# MCU_CTRL_MMR_MCU_CTRL_MMR_CFG0_04500000h register map
Vendor: Texas Instruments
Registers are 32-bit, read-write, reset 0x0 unless marked. A register's access mark holds for its fields unless they carry their own. Offsets are as the file gives them; [hi:lo] are bit positions; lines under a group give offsets from that group; {n}, {i} and the like mark numbered series.

## MCU_CTRL_MMR_CFG0 (part 2 of 3)
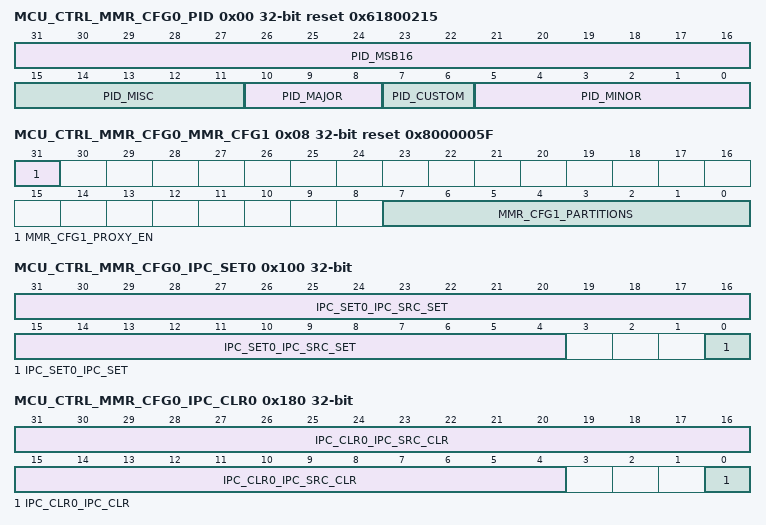
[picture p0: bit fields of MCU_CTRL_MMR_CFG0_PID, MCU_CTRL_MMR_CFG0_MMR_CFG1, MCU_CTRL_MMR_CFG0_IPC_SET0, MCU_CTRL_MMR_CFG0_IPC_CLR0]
0x00 MCU_CTRL_MMR_CFG0_PID ro reset 0x61800215
  [31:16] PID_MSB16 — Reset Source: mod_g_rst_n
  [15:11] PID_MISC — Reset Source: mod_g_rst_n
  [10:8] PID_MAJOR — Reset Source: mod_g_rst_n
  [7:6] PID_CUSTOM — Reset Source: mod_g_rst_n
  [5:0] PID_MINOR — Reset Source: mod_g_rst_n
0x08 MCU_CTRL_MMR_CFG0_MMR_CFG1 ro reset 0x8000005F
  [31] MMR_CFG1_PROXY_EN — Proxy addressing activated Reset Source: mod_por_rst_n
  [7:0] MMR_CFG1_PARTITIONS — Indicates present partitions Reset Source: mod_por_rst_n
0x100 MCU_CTRL_MMR_CFG0_IPC_SET0 access not given
  [31:4] IPC_SET0_IPC_SRC_SET — Read returns current valueWrite: 0 - No effect 1 - Sets both SRC_SETx and the SRC_CLRx bit in the corresponding IPC_CLR register Reset Source: mod_g_rst_n (access R/W1TS)
  [0] IPC_SET0_IPC_SET — Read returns 0Write: 0 - No effect 1 - Sets both the IPC_SET and the IPC_CLR bit in the corresponding IPC_CLR register Reset Source: mod_g_rst_n (access R/W1TS)
0x180 MCU_CTRL_MMR_CFG0_IPC_CLR0 access not given
  [31:4] IPC_CLR0_IPC_SRC_CLR — Read returns current valueWrite: 0 - No effect 1 - Clears both SRC_CLRx and the SRC_SETx bit in the corresponding IPC_GEN register Reset Source: mod_g_rst_n (access R/W1TC)
  [0] IPC_CLR0_IPC_CLR — Read returns current valueWrite: 0 - No effect 1 - Clears both IPC_CLR and the IPC_SET bit in the corresponding IPC_SET register Reset Source: mod_g_rst_n (access R/W1TC)
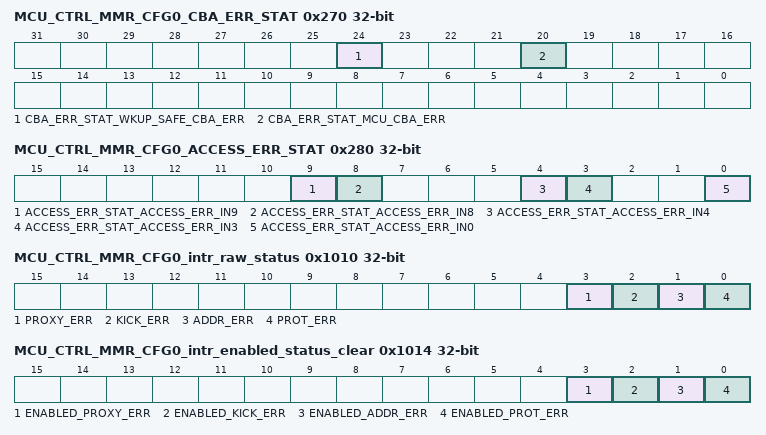
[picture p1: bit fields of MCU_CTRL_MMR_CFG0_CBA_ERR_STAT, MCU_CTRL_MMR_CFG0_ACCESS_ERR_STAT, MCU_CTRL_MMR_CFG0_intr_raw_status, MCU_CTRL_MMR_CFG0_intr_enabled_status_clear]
0x270 MCU_CTRL_MMR_CFG0_CBA_ERR_STAT ro
  [24] CBA_ERR_STAT_WKUP_SAFE_CBA_ERR — Access Error from Wkup Safe CBASS Reset Source: mod_g_rst_n
  [20] CBA_ERR_STAT_MCU_CBA_ERR — Access Error from MCU CBASS Reset Source: mod_g_rst_n
0x280 MCU_CTRL_MMR_CFG0_ACCESS_ERR_STAT ro
  [9] ACCESS_ERR_STAT_ACCESS_ERR_IN9 — Access Error Detected in MCU PadCfg MMR Reset Source: mod_por_rst_n
  [8] ACCESS_ERR_STAT_ACCESS_ERR_IN8 — Access Error Detected in MCU Ctrl MMR Reset Source: mod_por_rst_n
  [4] ACCESS_ERR_STAT_ACCESS_ERR_IN4 — Access Error Detected in MAIN PadCfg MMR Reset Source: mod_por_rst_n
  [3] ACCESS_ERR_STAT_ACCESS_ERR_IN3 — Access Error Detected in MAIN Ctrl MMR Reset Source: mod_por_rst_n
  [0] ACCESS_ERR_STAT_ACCESS_ERR_IN0 — Access Error Detected in WKUP Ctrl MMR Reset Source: mod_por_rst_n
{0x1008+0x4000*i} MCU_CTRL_MMR_CFG0_LOCK{i}_KICK0 (i=0..4)
  [31:0] LOCK{i}_KICK0 — - KICK0 component Reset Source: mod_g_rst_n
{0x100C+0x4000*i} MCU_CTRL_MMR_CFG0_LOCK{i}_KICK1 (i=0..4)
  [31:0] LOCK{i}_KICK1 — - KICK1 component Reset Source: mod_g_rst_n
0x1010 MCU_CTRL_MMR_CFG0_intr_raw_status access not given
  [3] PROXY_ERR — Proxy0 access violation error. Raw status is read. Write a 1 to set the status. Writing a 0 has no effect. Reset Source: mod_g_rst_n (access R/W1TS)
  [2] KICK_ERR — Kick access violation error. Raw status is read. Write a 1 to set the status. Writing a 0 has no effect. Reset Source: mod_g_rst_n (access R/W1TS)
  [1] ADDR_ERR — Addressing violation error. Raw status is read. Write a 1 to set the status. Writing a 0 has no effect. Reset Source: mod_g_rst_n (access R/W1TS)
  [0] PROT_ERR — Protection violation error. Raw status is read. Write a 1 to set the status. Writing a 0 has no effect. Reset Source: mod_g_rst_n (access R/W1TS)
0x1014 MCU_CTRL_MMR_CFG0_intr_enabled_status_clear access not given
  [3] ENABLED_PROXY_ERR — Proxy0 access violation error. Enabled status is read. Write a 1 to clear the status. Writing a 0 has no effect. Reset Source: mod_g_rst_n (access R/W1TC)
  [2] ENABLED_KICK_ERR — Kick access violation error. Enabled status is read. Write a 1 to clear the status. Writing a 0 has no effect. Reset Source: mod_g_rst_n (access R/W1TC)
  [1] ENABLED_ADDR_ERR — Addressing violation error. Enabled status is read. Write a 1 to clear the status. Writing a 0 has no effect. Reset Source: mod_g_rst_n (access R/W1TC)
  [0] ENABLED_PROT_ERR — Protection violation error. Enabled status is read. Write a 1 to clear the status. Writing a 0 has no effect. Reset Source: mod_g_rst_n (access R/W1TC)
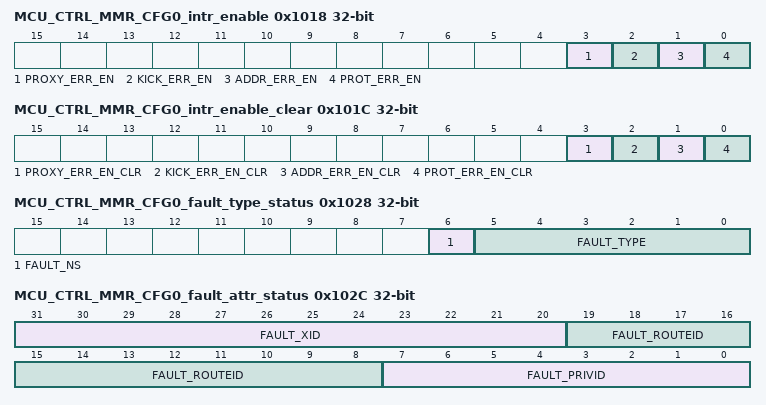
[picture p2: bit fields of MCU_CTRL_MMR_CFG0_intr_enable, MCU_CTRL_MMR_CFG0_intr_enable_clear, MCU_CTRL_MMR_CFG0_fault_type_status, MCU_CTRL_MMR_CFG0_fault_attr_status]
0x1018 MCU_CTRL_MMR_CFG0_intr_enable access not given
  [3] PROXY_ERR_EN — Proxy0 access violation error enable. Write a 1 to set the enable. Writing a 0 has no effect. Reset Source: mod_g_rst_n (access R/W1TS)
  [2] KICK_ERR_EN — Kick access violation error enable. Write a 1 to set the enable. Writing a 0 has no effect. Reset Source: mod_g_rst_n (access R/W1TS)
  [1] ADDR_ERR_EN — Addressing violation error enable. Write a 1 to set the enable. Writing a 0 has no effect. Reset Source: mod_g_rst_n (access R/W1TS)
  [0] PROT_ERR_EN — Protection violation error enable. Write a 1 to set the enable. Writing a 0 has no effect. Reset Source: mod_g_rst_n (access R/W1TS)
0x101C MCU_CTRL_MMR_CFG0_intr_enable_clear access not given
  [3] PROXY_ERR_EN_CLR — Proxy0 access violation error enable clear. Write a 1 to clear the enable. Writing a 0 has no effect. Reset Source: mod_g_rst_n (access R/W1TC)
  [2] KICK_ERR_EN_CLR — Kick access violation error enable clear. Write a 1 to clear the enable. Writing a 0 has no effect. Reset Source: mod_g_rst_n (access R/W1TC)
  [1] ADDR_ERR_EN_CLR — Addressing violation error enable clear. Write a 1 to clear the enable. Writing a 0 has no effect. Reset Source: mod_g_rst_n (access R/W1TC)
  [0] PROT_ERR_EN_CLR — Protection violation error enable clear. Write a 1 to clear the enable. Writing a 0 has no effect. Reset Source: mod_g_rst_n (access R/W1TC)
0x1020 MCU_CTRL_MMR_CFG0_eoi
  [7:0] EOI_VECTOR — EOI vector value. Write this with interrupt distribution value in the chip. Reset Source: mod_g_rst_n
0x1024 MCU_CTRL_MMR_CFG0_fault_address ro
  [31:0] FAULT_ADDR — Fault Address. Reset Source: mod_g_rst_n
0x1028 MCU_CTRL_MMR_CFG0_fault_type_status ro
  [6] FAULT_NS — Non-secure access. Reset Source: mod_g_rst_n
  [5:0] FAULT_TYPE — Fault Type 10_0000 = Supervisor read fault - priv = 1 dir = 1 dtype != 1 01_0000 = Supervisor write fault - priv = 1 dir = 0 00_1000 = Supervisor execute fault - priv = 1 dir = 1 dtype = 1 00_0100 = User read fault - priv = 0 dir = 1 dtype = 1 00_0010 = User write fault - priv = 0 dir = 0 00_0001 = User execute fault - priv = 0 dir = 1 dtype = 1 00_0000 = No fault Reset Source: mod_g_rst_n
0x102C MCU_CTRL_MMR_CFG0_fault_attr_status ro
  [31:20] FAULT_XID — XID. Reset Source: mod_g_rst_n
  [19:8] FAULT_ROUTEID — Route ID. Reset Source: mod_g_rst_n
  [7:0] FAULT_PRIVID — Privilege ID. Reset Source: mod_g_rst_n
0x1030 MCU_CTRL_MMR_CFG0_fault_clear wo
  [0] FAULT_CLR — Fault clear. Writing a 1 clears the current fault. Writing a 0 has no effect. Reset Source: mod_g_rst_n
{0x1100+4i} MCU_CTRL_MMR_CFG0_CLAIMREG_P0_R{i}_READONLY ro (i=0..5)
  [31:0] CLAIMREG_P0_R{i}_READONLY — Claim bits for Partition 0 Reset Source: mod_g_rst_n
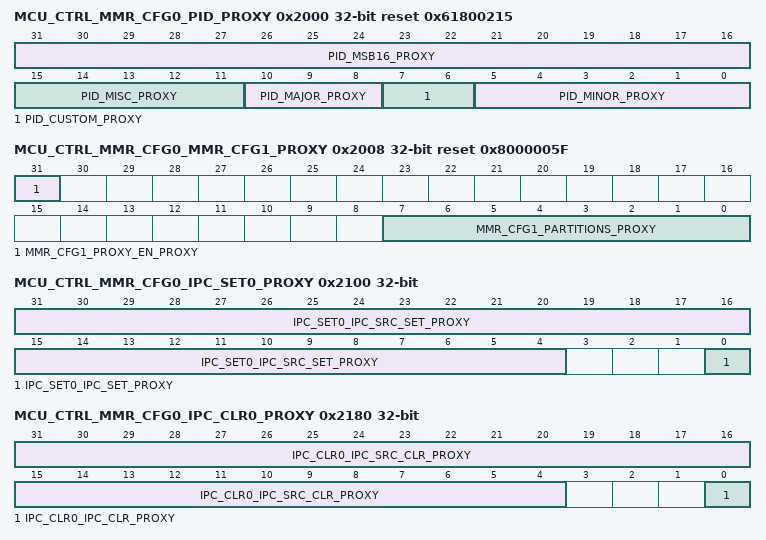
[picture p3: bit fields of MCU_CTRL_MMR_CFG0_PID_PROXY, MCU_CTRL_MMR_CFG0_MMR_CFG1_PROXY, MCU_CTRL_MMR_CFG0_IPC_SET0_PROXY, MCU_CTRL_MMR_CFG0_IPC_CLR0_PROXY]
0x2000 MCU_CTRL_MMR_CFG0_PID_PROXY ro reset 0x61800215
  [31:16] PID_MSB16_PROXY — Reset Source: mod_g_rst_n
  [15:11] PID_MISC_PROXY — Reset Source: mod_g_rst_n
  [10:8] PID_MAJOR_PROXY — Reset Source: mod_g_rst_n
  [7:6] PID_CUSTOM_PROXY — Reset Source: mod_g_rst_n
  [5:0] PID_MINOR_PROXY — Reset Source: mod_g_rst_n
0x2008 MCU_CTRL_MMR_CFG0_MMR_CFG1_PROXY ro reset 0x8000005F
  [31] MMR_CFG1_PROXY_EN_PROXY — Proxy addressing activated Reset Source: mod_por_rst_n
  [7:0] MMR_CFG1_PARTITIONS_PROXY — Indicates present partitions Reset Source: mod_por_rst_n
0x2100 MCU_CTRL_MMR_CFG0_IPC_SET0_PROXY access not given
  [31:4] IPC_SET0_IPC_SRC_SET_PROXY — Read returns current valueWrite: 0 - No effect 1 - Sets both SRC_SETx and the SRC_CLRx bit in the corresponding IPC_CLR register Reset Source: mod_g_rst_n (access R/W1TS)
  [0] IPC_SET0_IPC_SET_PROXY — Read returns 0Write: 0 - No effect 1 - Sets both the IPC_SET and the IPC_CLR bit in the corresponding IPC_CLR register Reset Source: mod_g_rst_n (access R/W1TS)
0x2180 MCU_CTRL_MMR_CFG0_IPC_CLR0_PROXY access not given
  [31:4] IPC_CLR0_IPC_SRC_CLR_PROXY — Read returns current valueWrite: 0 - No effect 1 - Clears both SRC_CLRx and the SRC_SETx bit in the corresponding IPC_GEN register Reset Source: mod_g_rst_n (access R/W1TC)
  [0] IPC_CLR0_IPC_CLR_PROXY — Read returns current valueWrite: 0 - No effect 1 - Clears both IPC_CLR and the IPC_SET bit in the corresponding IPC_SET register Reset Source: mod_g_rst_n (access R/W1TC)
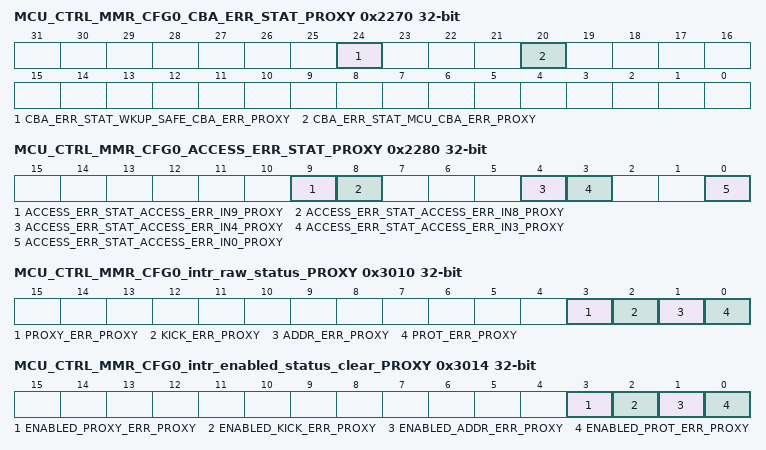
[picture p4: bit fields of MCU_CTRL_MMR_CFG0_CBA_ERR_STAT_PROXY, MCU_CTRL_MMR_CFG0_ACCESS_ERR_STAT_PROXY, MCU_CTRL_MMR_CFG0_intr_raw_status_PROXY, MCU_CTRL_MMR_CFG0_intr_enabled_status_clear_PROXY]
0x2270 MCU_CTRL_MMR_CFG0_CBA_ERR_STAT_PROXY ro
  [24] CBA_ERR_STAT_WKUP_SAFE_CBA_ERR_PROXY — Access Error from Wkup Safe CBASS Reset Source: mod_g_rst_n
  [20] CBA_ERR_STAT_MCU_CBA_ERR_PROXY — Access Error from MCU CBASS Reset Source: mod_g_rst_n
0x2280 MCU_CTRL_MMR_CFG0_ACCESS_ERR_STAT_PROXY ro
  [9] ACCESS_ERR_STAT_ACCESS_ERR_IN9_PROXY — Access Error Detected in MCU PadCfg MMR Reset Source: mod_por_rst_n
  [8] ACCESS_ERR_STAT_ACCESS_ERR_IN8_PROXY — Access Error Detected in MCU Ctrl MMR Reset Source: mod_por_rst_n
  [4] ACCESS_ERR_STAT_ACCESS_ERR_IN4_PROXY — Access Error Detected in MAIN PadCfg MMR Reset Source: mod_por_rst_n
  [3] ACCESS_ERR_STAT_ACCESS_ERR_IN3_PROXY — Access Error Detected in MAIN Ctrl MMR Reset Source: mod_por_rst_n
  [0] ACCESS_ERR_STAT_ACCESS_ERR_IN0_PROXY — Access Error Detected in WKUP Ctrl MMR Reset Source: mod_por_rst_n
{0x3008+0x4000*i} MCU_CTRL_MMR_CFG0_LOCK{i}_KICK0_PROXY (i=0..4)
  [31:0] LOCK{i}_KICK0_PROXY — - KICK0 component Reset Source: mod_g_rst_n
{0x300C+0x4000*i} MCU_CTRL_MMR_CFG0_LOCK{i}_KICK1_PROXY (i=0..4)
  [31:0] LOCK{i}_KICK1_PROXY — - KICK1 component Reset Source: mod_g_rst_n
0x3010 MCU_CTRL_MMR_CFG0_intr_raw_status_PROXY access not given
  [3] PROXY_ERR_PROXY — Proxy0 access violation error. Raw status is read. Write a 1 to set the status. Writing a 0 has no effect. Reset Source: mod_g_rst_n (access R/W1TS)
  [2] KICK_ERR_PROXY — Kick access violation error. Raw status is read. Write a 1 to set the status. Writing a 0 has no effect. Reset Source: mod_g_rst_n (access R/W1TS)
  [1] ADDR_ERR_PROXY — Addressing violation error. Raw status is read. Write a 1 to set the status. Writing a 0 has no effect. Reset Source: mod_g_rst_n (access R/W1TS)
  [0] PROT_ERR_PROXY — Protection violation error. Raw status is read. Write a 1 to set the status. Writing a 0 has no effect. Reset Source: mod_g_rst_n (access R/W1TS)
0x3014 MCU_CTRL_MMR_CFG0_intr_enabled_status_clear_PROXY access not given
  [3] ENABLED_PROXY_ERR_PROXY — Proxy0 access violation error. Enabled status is read. Write a 1 to clear the status. Writing a 0 has no effect. Reset Source: mod_g_rst_n (access R/W1TC)
  [2] ENABLED_KICK_ERR_PROXY — Kick access violation error. Enabled status is read. Write a 1 to clear the status. Writing a 0 has no effect. Reset Source: mod_g_rst_n (access R/W1TC)
  [1] ENABLED_ADDR_ERR_PROXY — Addressing violation error. Enabled status is read. Write a 1 to clear the status. Writing a 0 has no effect. Reset Source: mod_g_rst_n (access R/W1TC)
  [0] ENABLED_PROT_ERR_PROXY — Protection violation error. Enabled status is read. Write a 1 to clear the status. Writing a 0 has no effect. Reset Source: mod_g_rst_n (access R/W1TC)
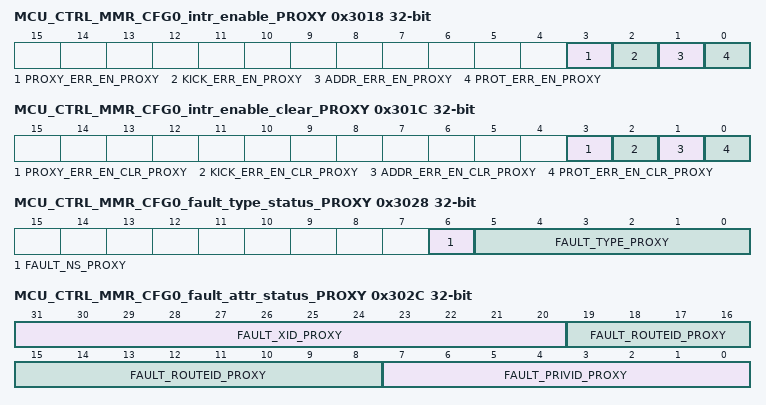
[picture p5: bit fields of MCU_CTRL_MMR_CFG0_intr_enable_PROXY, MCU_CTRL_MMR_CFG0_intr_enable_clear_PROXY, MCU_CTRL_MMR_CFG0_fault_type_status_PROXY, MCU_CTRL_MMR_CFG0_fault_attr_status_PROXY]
0x3018 MCU_CTRL_MMR_CFG0_intr_enable_PROXY access not given
  [3] PROXY_ERR_EN_PROXY — Proxy0 access violation error enable. Write a 1 to set the enable. Writing a 0 has no effect. Reset Source: mod_g_rst_n (access R/W1TS)
  [2] KICK_ERR_EN_PROXY — Kick access violation error enable. Write a 1 to set the enable. Writing a 0 has no effect. Reset Source: mod_g_rst_n (access R/W1TS)
  [1] ADDR_ERR_EN_PROXY — Addressing violation error enable. Write a 1 to set the enable. Writing a 0 has no effect. Reset Source: mod_g_rst_n (access R/W1TS)
  [0] PROT_ERR_EN_PROXY — Protection violation error enable. Write a 1 to set the enable. Writing a 0 has no effect. Reset Source: mod_g_rst_n (access R/W1TS)
0x301C MCU_CTRL_MMR_CFG0_intr_enable_clear_PROXY access not given
  [3] PROXY_ERR_EN_CLR_PROXY — Proxy0 access violation error enable clear. Write a 1 to clear the enable. Writing a 0 has no effect. Reset Source: mod_g_rst_n (access R/W1TC)
  [2] KICK_ERR_EN_CLR_PROXY — Kick access violation error enable clear. Write a 1 to clear the enable. Writing a 0 has no effect. Reset Source: mod_g_rst_n (access R/W1TC)
  [1] ADDR_ERR_EN_CLR_PROXY — Addressing violation error enable clear. Write a 1 to clear the enable. Writing a 0 has no effect. Reset Source: mod_g_rst_n (access R/W1TC)
  [0] PROT_ERR_EN_CLR_PROXY — Protection violation error enable clear. Write a 1 to clear the enable. Writing a 0 has no effect. Reset Source: mod_g_rst_n (access R/W1TC)
0x3020 MCU_CTRL_MMR_CFG0_eoi_PROXY
  [7:0] EOI_VECTOR_PROXY — EOI vector value. Write this with interrupt distribution value in the chip. Reset Source: mod_g_rst_n
0x3024 MCU_CTRL_MMR_CFG0_fault_address_PROXY ro
  [31:0] FAULT_ADDR_PROXY — Fault Address. Reset Source: mod_g_rst_n
0x3028 MCU_CTRL_MMR_CFG0_fault_type_status_PROXY ro
  [6] FAULT_NS_PROXY — Non-secure access. Reset Source: mod_g_rst_n
  [5:0] FAULT_TYPE_PROXY — Fault Type 10_0000 = Supervisor read fault - priv = 1 dir = 1 dtype != 1 01_0000 = Supervisor write fault - priv = 1 dir = 0 00_1000 = Supervisor execute fault - priv = 1 dir = 1 dtype = 1 00_0100 = User read fault - priv = 0 dir = 1 dtype = 1 00_0010 = User write fault - priv = 0 dir = 0 00_0001 = User execute fault - priv = 0 dir = 1 dtype = 1 00_0000 = No fault Reset Source: mod_g_rst_n
0x302C MCU_CTRL_MMR_CFG0_fault_attr_status_PROXY ro
  [31:20] FAULT_XID_PROXY — XID. Reset Source: mod_g_rst_n
  [19:8] FAULT_ROUTEID_PROXY — Route ID. Reset Source: mod_g_rst_n
  [7:0] FAULT_PRIVID_PROXY — Privilege ID. Reset Source: mod_g_rst_n
0x3030 MCU_CTRL_MMR_CFG0_fault_clear_PROXY wo
  [0] FAULT_CLR_PROXY — Fault clear. Writing a 1 clears the current fault. Writing a 0 has no effect. Reset Source: mod_g_rst_n
{0x3100+4i} MCU_CTRL_MMR_CFG0_CLAIMREG_P0_R{i} (i=0..5)
  [31:0] CLAIMREG_P0_R{i} — Claim bits for Partition 0 Reset Source: mod_g_rst_n
0x4020 MCU_CTRL_MMR_CFG0_MCU_GPIO_CTRL
  [0] MCU_GPIO_CTRL_WAKEN — Activates MCU_GPIO wakeup event operation by controling the MCU_GPIO LPSC clockstop_ack behavior.Field values (Others are reserved):1'b0 - No MCU_GPIO wakeup support. MCU_GPIO vbus clock is gated on clkstop_ack from MCU_GPIO to LPSC1'b1 - MCU_GPIO wakeup activated. MCU_GPIO vbus clock is NOT gated on LPSC clockstop_req. MCU_GPIO LPSC clkstop_ack input is driven by clkstop_req output. Reset Source: mod_por_rst_n
{0x4080+4i} MCU_CTRL_MMR_CFG0_DBOUNCE_CFG{i} (i=1..6)
  [5:0] DBOUNCE_CFG{i}_DB_CFG — Configures the debounce period used for I/Os with debounce_sel{i} activated. Reset Source: mod_por_rst_n
0x40A0 MCU_CTRL_MMR_CFG0_TEMP_DIODE_TRIM ro
  [13:0] TEMP_DIODE_TRIM_TRIM — Sets the diode non-ideality factor (n), starting from 100th place decimal and going down Reset Source: mod_por_rst_n
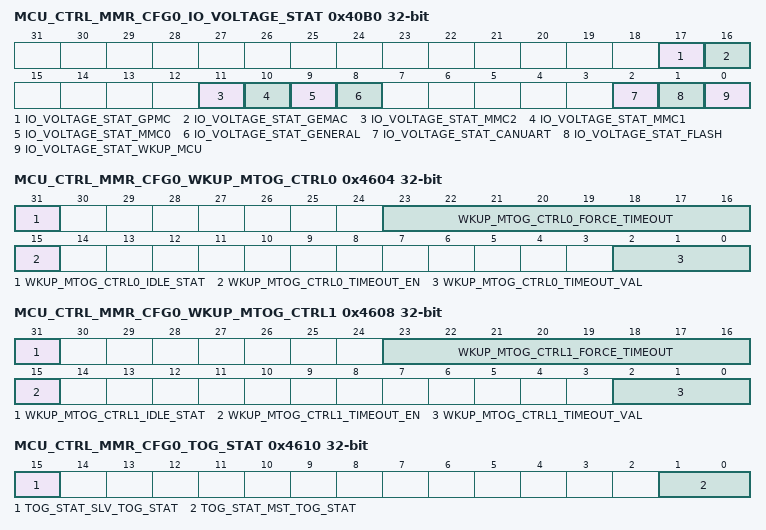
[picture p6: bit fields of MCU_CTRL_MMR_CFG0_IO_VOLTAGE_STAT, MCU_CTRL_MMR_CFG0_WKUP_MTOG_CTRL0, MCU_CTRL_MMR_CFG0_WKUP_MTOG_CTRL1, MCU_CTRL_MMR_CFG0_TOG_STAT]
0x40B0 MCU_CTRL_MMR_CFG0_IO_VOLTAGE_STAT ro
  [17] IO_VOLTAGE_STAT_GPMC — Indicates the voltage for the GPMC I/O group (VDDSHV3)Field values (others are reserved):1'b0 - I/O group is set for 3.3V1'b1 - I/O group is set for 1.8V Reset Source: mod_por_rst_n
  [16] IO_VOLTAGE_STAT_GEMAC — Indicates the voltage for the GEMAC I/O group (VDDSHV2)Field values (others are reserved):1'b0 - I/O group is set for 3.3V1'b1 - I/O group is set for 1.8V Reset Source: mod_por_rst_n
  [11] IO_VOLTAGE_STAT_MMC2 — Indicates the voltage for the MMC2 I/O group (VDDSHV6)Field values (others are reserved):1'b0 - I/O group is set for 3.3V1'b1 - I/O group is set for 1.8V Reset Source: mod_por_rst_n
  [10] IO_VOLTAGE_STAT_MMC1 — Indicates the voltage for the MMC1 I/O group (VDDSHV5)Field values (others are reserved):1'b0 - I/O group is set for 3.3V1'b1 - I/O group is set for 1.8V Reset Source: mod_por_rst_n
  [9] IO_VOLTAGE_STAT_MMC0 — Indicates the voltage for the MMC0 I/O group (VDDSHV4)Field values (others are reserved):1'b0 - I/O group is set for 3.3V1'b1 - I/O group is set for 1.8V Reset Source: mod_por_rst_n
  [8] IO_VOLTAGE_STAT_GENERAL — Indicates the voltage for the General I/O group (VDDSHV0)Field values (others are reserved):1'b0 - I/O group is set for 3.3V1'b1 - I/O group is set for 1.8V Reset Source: mod_por_rst_n
  [2] IO_VOLTAGE_STAT_CANUART — Indicates the voltage for the CANUART I/O group (VDDSHV_WKUP)Field values (others are reserved):1'b0 - I/O group is set for 3.3V1'b1 - I/O group is set for 1.8V Reset Source: mod_por_rst_n
  [1] IO_VOLTAGE_STAT_FLASH — Indicates the voltage for the Flash I/O group (VDDSHV1)Field values (others are reserved):1'b0 - I/O group is set for 3.3V1'b1 - I/O group is set for 1.8V Reset Source: mod_por_rst_n
  [0] IO_VOLTAGE_STAT_WKUP_MCU — Indicates the voltage for the WKUP_MCU I/O group (VDDSHV_MCU)Field values (others are reserved):1'b0 - I/O group is set for 3.3V1'b1 - I/O group is set for 1.8V Reset Source: mod_por_rst_n
0x4204 MCU_CTRL_MMR_CFG0_MCU_TIMER1_CTRL
  [8] MCU_TIMER1_CTRL_CASCADE_EN — Activates cascading of TIMER1 to TIMER0 Reset Source: mod_g_rst_n
0x420C MCU_CTRL_MMR_CFG0_MCU_TIMER3_CTRL
  [8] MCU_TIMER3_CTRL_CASCADE_EN — Activates cascading of TIMER3 to TIMER2 Reset Source: mod_g_rst_n
0x42E0 MCU_CTRL_MMR_CFG0_MCU_I2C0_CTRL
  [0] MCU_I2C0_CTRL_HS_MCS_EN — HS Mode controller current source activate.When set, activates the current-source pull-up on the SCL output. Only one controller on the I2C bus should activate SCL current sourcing. Reset Source: mod_g_rst_n
0x4604 MCU_CTRL_MMR_CFG0_WKUP_MTOG_CTRL0 access per field
  [31] WKUP_MTOG_CTRL0_IDLE_STAT ro — Idle Status Reset Source: mod_g_rst_n
  [23:16] WKUP_MTOG_CTRL0_FORCE_TIMEOUT rw — Force TimoutThis is a fault tolerant bitfield.Forces a flush of the interface transactions. This bitfield is only relevant if timeout_en=1. After forcing a timeout by Writing the encoded value, the force_timeout and timeout_en bitfields mut be cleared to clear the timeout before re-enabling the gasket.8'h95 - Force a gasket timeoutAll others - Normal operation Reset Source: mod_g_rst_n
  [15] WKUP_MTOG_CTRL0_TIMEOUT_EN rw — Timeout Activate 1'b0 - Deactivate the gasket. Clear the interrupt and reset the counter 1'b1 - Activate the timeout gasket functions Reset Source: mod_g_rst_n
  [2:0] WKUP_MTOG_CTRL0_TIMEOUT_VAL rw — Gasket Timeout ValueSelects the number of clock cycles before the interface is considered to have timed out Reset Source: mod_g_rst_n
0x4608 MCU_CTRL_MMR_CFG0_WKUP_MTOG_CTRL1 access per field
  [31] WKUP_MTOG_CTRL1_IDLE_STAT ro — Idle Status Reset Source: mod_g_rst_n
  [23:16] WKUP_MTOG_CTRL1_FORCE_TIMEOUT rw — Force TimoutThis is a fault tolerant bitfield.Forces a flush of the interface transactions. This bitfield is only relevant if timeout_en=1. After forcing a timeout by Writing the encoded value, the force_timeout and timeout_en bitfields mut be cleared to clear the timeout before re-enabling the gasket.8'h95 - Force a gasket timeoutAll others - Normal operation Reset Source: mod_g_rst_n
  [15] WKUP_MTOG_CTRL1_TIMEOUT_EN rw — Timeout Activate 1'b0 - Deactivate the gasket. Clear the interrupt and reset the counter 1'b1 - Activate the timeout gasket functions Reset Source: mod_g_rst_n
  [2:0] WKUP_MTOG_CTRL1_TIMEOUT_VAL rw — Gasket Timeout ValueSelects the number of clock cycles before the interface is considered to have timed out Reset Source: mod_g_rst_n
0x4610 MCU_CTRL_MMR_CFG0_TOG_STAT ro
  [15] TOG_STAT_SLV_TOG_STAT — Error Status of Target Timeout GasketsField values (others are reserved):1'b0 - No Error1'b1 - Error from mcu2dm timeout gasket MCU_TIMEOUT0 Reset Source: mod_g_rst_n
  [1:0] TOG_STAT_MST_TOG_STAT — Error Status of Target Timeout GasketsField values (others are reserved):2'b00 - No Error2'b01 - Error from dm2mcu WKUP_TIMEOUT1 gasket2'b10 - Error from dm2ws WKUP_TIMEOUT0 gasket2'b11 - Error from both dm2mcu and dm2ws WKUP_TIMEOUT1 and WKUP_TIMEOUT0 gaskets Reset Source: mod_g_rst_n
{0x5100+4i} MCU_CTRL_MMR_CFG0_CLAIMREG_P1_R{i}_READONLY ro (i=0..12)
  [31:0] CLAIMREG_P1_R{i}_READONLY — Claim bits for Partition 1 Reset Source: mod_g_rst_n
0x6020 MCU_CTRL_MMR_CFG0_MCU_GPIO_CTRL_PROXY
  [0] MCU_GPIO_CTRL_WAKEN_PROXY — Activates MCU_GPIO wakeup event operation by controling the MCU_GPIO LPSC clockstop_ack behavior.Field values (Others are reserved):1'b0 - No MCU_GPIO wakeup support. MCU_GPIO vbus clock is gated on clkstop_ack from MCU_GPIO to LPSC1'b1 - MCU_GPIO wakeup activated. MCU_GPIO vbus clock is NOT gated on LPSC clockstop_req. MCU_GPIO LPSC clkstop_ack input is driven by clkstop_req output. Reset Source: mod_por_rst_n
{0x6080+4i} MCU_CTRL_MMR_CFG0_DBOUNCE_CFG{i}_PROXY (i=1..6)
  [5:0] DBOUNCE_CFG{i}_DB_CFG_PROXY — Configures the debounce period used for I/Os with debounce_sel{i} activated. Reset Source: mod_por_rst_n
0x60A0 MCU_CTRL_MMR_CFG0_TEMP_DIODE_TRIM_PROXY ro
  [13:0] TEMP_DIODE_TRIM_TRIM_PROXY — Sets the diode non-ideality factor (n), starting from 100th place decimal and going down Reset Source: mod_por_rst_n
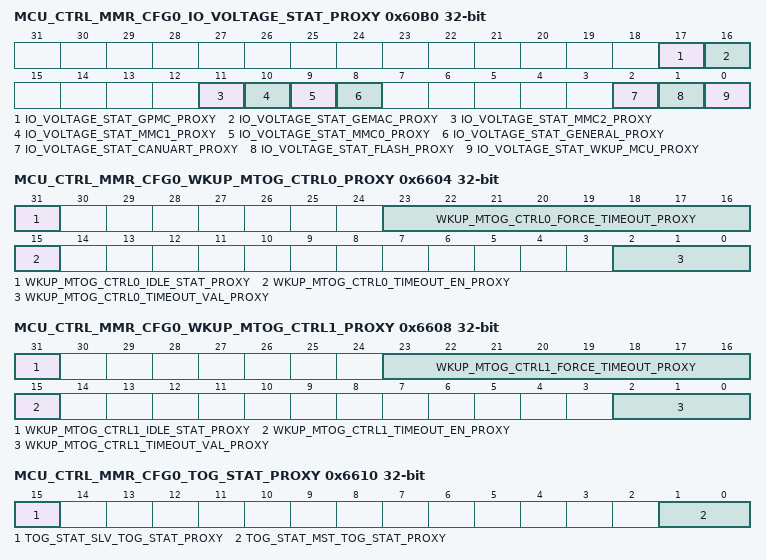
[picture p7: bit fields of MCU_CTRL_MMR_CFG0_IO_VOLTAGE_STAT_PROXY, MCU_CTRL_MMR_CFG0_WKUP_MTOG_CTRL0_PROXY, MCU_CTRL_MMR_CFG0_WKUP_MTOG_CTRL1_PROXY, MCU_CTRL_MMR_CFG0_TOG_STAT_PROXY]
0x60B0 MCU_CTRL_MMR_CFG0_IO_VOLTAGE_STAT_PROXY ro
  [17] IO_VOLTAGE_STAT_GPMC_PROXY — Indicates the voltage for the GPMC I/O group (VDDSHV3)Field values (others are reserved):1'b0 - I/O group is set for 3.3V1'b1 - I/O group is set for 1.8V Reset Source: mod_por_rst_n
  [16] IO_VOLTAGE_STAT_GEMAC_PROXY — Indicates the voltage for the GEMAC I/O group (VDDSHV2)Field values (others are reserved):1'b0 - I/O group is set for 3.3V1'b1 - I/O group is set for 1.8V Reset Source: mod_por_rst_n
  [11] IO_VOLTAGE_STAT_MMC2_PROXY — Indicates the voltage for the MMC2 I/O group (VDDSHV6)Field values (others are reserved):1'b0 - I/O group is set for 3.3V1'b1 - I/O group is set for 1.8V Reset Source: mod_por_rst_n
  [10] IO_VOLTAGE_STAT_MMC1_PROXY — Indicates the voltage for the MMC1 I/O group (VDDSHV5)Field values (others are reserved):1'b0 - I/O group is set for 3.3V1'b1 - I/O group is set for 1.8V Reset Source: mod_por_rst_n
  [9] IO_VOLTAGE_STAT_MMC0_PROXY — Indicates the voltage for the MMC0 I/O group (VDDSHV4)Field values (others are reserved):1'b0 - I/O group is set for 3.3V1'b1 - I/O group is set for 1.8V Reset Source: mod_por_rst_n
  [8] IO_VOLTAGE_STAT_GENERAL_PROXY — Indicates the voltage for the General I/O group (VDDSHV0)Field values (others are reserved):1'b0 - I/O group is set for 3.3V1'b1 - I/O group is set for 1.8V Reset Source: mod_por_rst_n
  [2] IO_VOLTAGE_STAT_CANUART_PROXY — Indicates the voltage for the CANUART I/O group (VDDSHV_WKUP)Field values (others are reserved):1'b0 - I/O group is set for 3.3V1'b1 - I/O group is set for 1.8V Reset Source: mod_por_rst_n
  [1] IO_VOLTAGE_STAT_FLASH_PROXY — Indicates the voltage for the Flash I/O group (VDDSHV1)Field values (others are reserved):1'b0 - I/O group is set for 3.3V1'b1 - I/O group is set for 1.8V Reset Source: mod_por_rst_n
  [0] IO_VOLTAGE_STAT_WKUP_MCU_PROXY — Indicates the voltage for the WKUP_MCU I/O group (VDDSHV_MCU)Field values (others are reserved):1'b0 - I/O group is set for 3.3V1'b1 - I/O group is set for 1.8V Reset Source: mod_por_rst_n
0x6204 MCU_CTRL_MMR_CFG0_MCU_TIMER1_CTRL_PROXY
  [8] MCU_TIMER1_CTRL_CASCADE_EN_PROXY — Activates cascading of TIMER1 to TIMER0 Reset Source: mod_g_rst_n
0x620C MCU_CTRL_MMR_CFG0_MCU_TIMER3_CTRL_PROXY
  [8] MCU_TIMER3_CTRL_CASCADE_EN_PROXY — Activates cascading of TIMER3 to TIMER2 Reset Source: mod_g_rst_n
0x62E0 MCU_CTRL_MMR_CFG0_MCU_I2C0_CTRL_PROXY
  [0] MCU_I2C0_CTRL_HS_MCS_EN_PROXY — HS Mode controller current source activate.When set, activates the current-source pull-up on the SCL output. Only one controller on the I2C bus should activate SCL current sourcing. Reset Source: mod_g_rst_n
0x6604 MCU_CTRL_MMR_CFG0_WKUP_MTOG_CTRL0_PROXY access per field
  [31] WKUP_MTOG_CTRL0_IDLE_STAT_PROXY ro — Idle Status Reset Source: mod_g_rst_n
  [23:16] WKUP_MTOG_CTRL0_FORCE_TIMEOUT_PROXY rw — Force TimoutThis is a fault tolerant bitfield.Forces a flush of the interface transactions. This bitfield is only relevant if timeout_en=1. After forcing a timeout by Writing the encoded value, the force_timeout and timeout_en bitfields mut be cleared to clear the timeout before re-enabling the gasket.8'h95 - Force a gasket timeoutAll others - Normal operation Reset Source: mod_g_rst_n
  [15] WKUP_MTOG_CTRL0_TIMEOUT_EN_PROXY rw — Timeout Activate 1'b0 - Deactivate the gasket. Clear the interrupt and reset the counter 1'b1 - Activate the timeout gasket functions Reset Source: mod_g_rst_n
  [2:0] WKUP_MTOG_CTRL0_TIMEOUT_VAL_PROXY rw — Gasket Timeout ValueSelects the number of clock cycles before the interface is considered to have timed out Reset Source: mod_g_rst_n
0x6608 MCU_CTRL_MMR_CFG0_WKUP_MTOG_CTRL1_PROXY access per field
  [31] WKUP_MTOG_CTRL1_IDLE_STAT_PROXY ro — Idle Status Reset Source: mod_g_rst_n
  [23:16] WKUP_MTOG_CTRL1_FORCE_TIMEOUT_PROXY rw — Force TimoutThis is a fault tolerant bitfield.Forces a flush of the interface transactions. This bitfield is only relevant if timeout_en=1. After forcing a timeout by Writing the encoded value, the force_timeout and timeout_en bitfields mut be cleared to clear the timeout before re-enabling the gasket.8'h95 - Force a gasket timeoutAll others - Normal operation Reset Source: mod_g_rst_n
  [15] WKUP_MTOG_CTRL1_TIMEOUT_EN_PROXY rw — Timeout Activate 1'b0 - Deactivate the gasket. Clear the interrupt and reset the counter 1'b1 - Activate the timeout gasket functions Reset Source: mod_g_rst_n
  [2:0] WKUP_MTOG_CTRL1_TIMEOUT_VAL_PROXY rw — Gasket Timeout ValueSelects the number of clock cycles before the interface is considered to have timed out Reset Source: mod_g_rst_n
0x6610 MCU_CTRL_MMR_CFG0_TOG_STAT_PROXY ro
  [15] TOG_STAT_SLV_TOG_STAT_PROXY — Error Status of Target Timeout GasketsField values (others are reserved):1'b0 - No Error1'b1 - Error from mcu2dm timeout gasket MCU_TIMEOUT0 Reset Source: mod_g_rst_n
  [1:0] TOG_STAT_MST_TOG_STAT_PROXY — Error Status of Target Timeout GasketsField values (others are reserved):2'b00 - No Error2'b01 - Error from dm2mcu WKUP_TIMEOUT1 gasket2'b10 - Error from dm2ws WKUP_TIMEOUT0 gasket2'b11 - Error from both dm2mcu and dm2ws WKUP_TIMEOUT1 and WKUP_TIMEOUT0 gaskets Reset Source: mod_g_rst_n
{0x7100+4i} MCU_CTRL_MMR_CFG0_CLAIMREG_P1_R{i} (i=0..12)
  [31:0] CLAIMREG_P1_R{i} — Claim bits for Partition 1 Reset Source: mod_g_rst_n
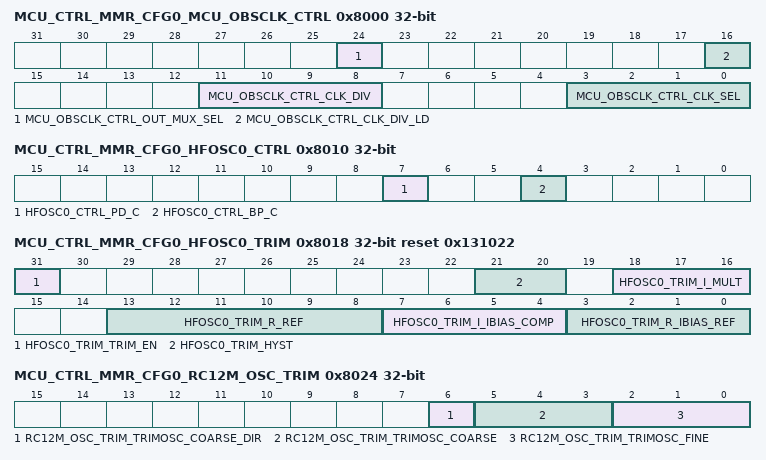
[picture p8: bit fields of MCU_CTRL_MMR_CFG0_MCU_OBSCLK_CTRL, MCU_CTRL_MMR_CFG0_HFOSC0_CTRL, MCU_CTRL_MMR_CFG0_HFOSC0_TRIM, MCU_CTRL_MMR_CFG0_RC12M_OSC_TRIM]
0x8000 MCU_CTRL_MMR_CFG0_MCU_OBSCLK_CTRL
  [24] MCU_OBSCLK_CTRL_OUT_MUX_SEL — MCU_OBSCLK pin output mux selection.Note, HFOSC0_CLK is a direct output from the HFOSC0, distinct from HFOSC0_CLKOUT.Note, when HFOSC0_CLK is selected (1'b1) the MCU_OBSCLK_CTRL_clk_sel field must be programmed to 4'b0001. 1'b0 - The output of the MCU_OBSCLK output divider is output on the pin 1'b1 - HFOSC0_CLK is output on the pin Reset Source: mod_por_rst_n
  [16] MCU_OBSCLK_CTRL_CLK_DIV_LD — Load the output divider valueWriting 1 to this bit will generate a load pulse to load the OBSCLK divider value. This bit can be cleared but must not be set in the same write cycle in which the clk_div value is changed. Reset Source: mod_por_rst_n
  [11:8] MCU_OBSCLK_CTRL_CLK_DIV — MCU_OBSCLK pin clock selection output dividerOutput clock is divided by clk_div+1 Reset Source: mod_por_rst_n
  [3:0] MCU_OBSCLK_CTRL_CLK_SEL — MCU_OBSCLK pin clock selectionField values (others are reserved):4'b0000 - CLK_12M_RC4'b0001 - '0'4'b0010 - MCU_PLL0_HSDIV0_CLKOUT4'b0011 - MCU_PLL0_HSDIV4_CLKOUT4'b0100 - MCU_PLLCTRL_OBSCLK4'b0101 - CLK_32K_RC4'b0110 - HFOSC0_CLKOUT4'b0111 - HFOSC0_CLKOUT_32K4'b1000 - MCU_SYSCLK04'b1001 - DEVICE_CLKOUT_32K Reset Source: mod_por_rst_n
0x8010 MCU_CTRL_MMR_CFG0_HFOSC0_CTRL
  [7] HFOSC0_CTRL_PD_C — Oscillator powerdown control. When set, oscillator is deactivated. Oscillator output is tristated if bp_c=0 Reset Source: mod_por_rst_n
  [4] HFOSC0_CTRL_BP_C — Reserved - Must Write '0' Reset Source: mod_por_rst_n
0x8018 MCU_CTRL_MMR_CFG0_HFOSC0_TRIM reset 0x131022
  [31] HFOSC0_TRIM_TRIM_EN — Apply MMR values to OSC trim inputs instead of tie-offs Reset Source: mod_por_rst_n
  [21:20] HFOSC0_TRIM_HYST — Sets comparator hysterisis Reset Source: mod_por_rst_n
  [18:16] HFOSC0_TRIM_I_MULT — AGC AMP current multiplication gain Reset Source: mod_por_rst_n
  [13:8] HFOSC0_TRIM_R_REF — Sets the AMP AGC bias current Reset Source: mod_por_rst_n
  [7:4] HFOSC0_TRIM_I_IBIAS_COMP — Sets the COMP bias current Reset Source: mod_por_rst_n
  [3:0] HFOSC0_TRIM_R_IBIAS_REF — Sets the base IBIAS reference Reset Source: mod_por_rst_n
0x8020 MCU_CTRL_MMR_CFG0_HFOSC0_STAT ro
  [0] HFOSC0_STAT_DS_ON_WFI_STAT — Allows MCU to monitor the DM attempting a Deep Sleep Reset Source: mod_g_rst_n
0x8024 MCU_CTRL_MMR_CFG0_RC12M_OSC_TRIM
  [6] RC12M_OSC_TRIM_TRIMOSC_COARSE_DIR — Coarse adjustment direction. If output is greater than 12.5 0 - Coarse adjustment decreases frequency 1 - Coarse adjustment increases frequency Reset Source: mod_por_rst_n
  [5:3] RC12M_OSC_TRIM_TRIMOSC_COARSE — Coarse adjustment. Frequency is decreased or increased by 1.25 MHz per value based on the trimosc_coarse_dir value. Reset Source: mod_por_rst_n
  [2:0] RC12M_OSC_TRIM_TRIMOSC_FINE — Fine adjustment. Decreases the frequency by 250 KHz per value. Reset Source: mod_por_rst_n
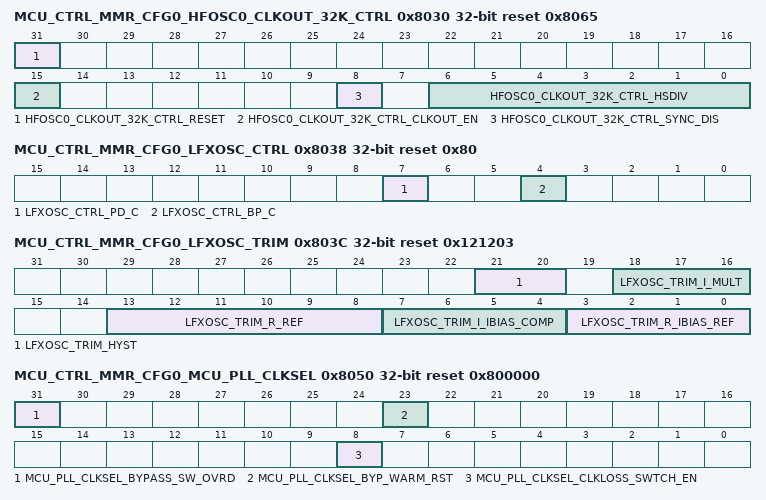
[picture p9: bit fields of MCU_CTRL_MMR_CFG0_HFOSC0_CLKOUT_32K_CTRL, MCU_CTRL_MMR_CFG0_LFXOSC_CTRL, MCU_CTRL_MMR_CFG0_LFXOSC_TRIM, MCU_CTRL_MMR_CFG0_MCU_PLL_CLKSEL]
0x8030 MCU_CTRL_MMR_CFG0_HFOSC0_CLKOUT_32K_CTRL reset 0x8065
  [31] HFOSC0_CLKOUT_32K_CTRL_RESET — Asynchronous Divider Reset1 = Divider is Reset, HFOSC0_CLKOUT32K reset.0 = Divider out of reset, HFOSC0_CLKOUT_32K running. Reset Source: sys_por_rst_n
  [15] HFOSC0_CLKOUT_32K_CTRL_CLKOUT_EN — HFOSC0_CLKOUT_32K activate: 0 = Synchronously Deactivate HFOSC0_CLKOUT_32KHz 1 = Synchronously Activate HFOSC0_CKLKOUT_32KHz Reset Source: sys_por_rst_n
  [8] HFOSC0_CLKOUT_32K_CTRL_SYNC_DIS — HFOSC0_CLKOUT_32K Synchronize Deactivate 0 = Divider Updates are shadowed and take effect on counter reset. 1 = Divider Updates are immediate and hazardousDo not set this bit to 1'b1 during normal use. Reset Source: sys_por_rst_n
  [6:0] HFOSC0_CLKOUT_32K_CTRL_HSDIV — HFOSC0_CLKOUT_32K divider:HFOSC0_CLKKOUT_32K Frequency = HFOSC0 Frequency / [8 * (hsdiv + 1)]Ex. HFOSC0 Frequency = 26MHz. hsdiv = 101 (Default)HFOSC0_CLKOUT_32K = 26MHz / (8 * (101+1)) = 26MHz / 816 = 31.9 KHz Reset Source: sys_por_rst_n
0x8038 MCU_CTRL_MMR_CFG0_LFXOSC_CTRL reset 0x80
  [7] LFXOSC_CTRL_PD_C — Oscillator powerdown control. When set, oscillator is deactivated. Oscillator output is tristated if bp_c=0 Reset Source: mod_por_rst_n
  [4] LFXOSC_CTRL_BP_C — Oscillator bypass control. When set, oscillator is in bypass mode Reset Source: mod_por_rst_n
0x803C MCU_CTRL_MMR_CFG0_LFXOSC_TRIM reset 0x121203
  [21:20] LFXOSC_TRIM_HYST — Sets comparator hysterisisField values (others are reserved):2'b00 - Hysteresis deactivated2'b01 - Type 1 hysteresis activated (Default)2'b10 - Type 2 hysteresis activated2'b11 - Both types 1 & 2 hysteresis activated Reset Source: mod_por_rst_n
  [18:16] LFXOSC_TRIM_I_MULT — AGC AMP current multiplication gainField values (others are reserved):3'b000 - 3x AMP_AGC IBIAS3'b001 - 4x AMP_AGC IBIAS3'b010 - 5x AMP_AGC IBIAS (Default)3'b011 - 6x AMP_AGC IBIAS3'b100 - 7x AMP_AGC IBIAS3'b101 - 8x AMP_AGC IBIAS3'b110 - 9x AMP_AGC IBIAS3'b111 - 10x AMP_AGC IBIAS Reset Source: mod_por_rst_n
  [13:8] LFXOSC_TRIM_R_REF — Sets the AMP AGC bias currentField values (others are reserved):6'b000000 - 0 K Ohm6'b000001 - 24 K Ohm6'b000010 - 48 K Ohm6'b000011 - 73 K Ohm6'b000100 - 97 K Ohm6'b000101 - 121 K Ohm6'b000110 - 145 K Ohm6'b000111 - 169 K Ohm6'b001000 - 193 K Ohm6'b001001 - 218 K Ohm6'b001010 - 242 K Ohm6'b001011 - 266 K Ohm6'b001100 - 290 K Ohm6'b001101 - 314 K Ohm6'b001110 - 338 K Ohm6'b001111 - 363 K Ohm6'b010000 - 387 K Ohm6'b010001 - 411 K Ohm6'b010010 - 435 K Ohm (Default)6'b010011 - 459 K Ohm6'b010100 - 483 K Ohm6'b010101 - 508 K Ohm6'b010110 - 532 K Ohm6'b010111 - 556 K Ohm6'b011000 - 580 K Ohm6'b011001 - 604 K Ohm6'b011010 - 628 K Ohm6'b011011 - 653 K Ohm6'b011100 - 677 K Ohm6'b011101 - 701 K Ohm6'b011110 - 725 K Ohm6'b011111 - 749 K Ohm6'b100000 - 773 K Ohm6'b100001 - 798 K Ohm6'b100010 - 822 K Ohm6'b100011 - 846 K Ohm6'b100100 - 870 K Ohm6'b100101 - 894 K Ohm6'b100110 - 918 K Ohm6'b100111 - 943 K Ohm6'b101000 - 967 K Ohm6'b101001 - 991 K Ohm6'b101010 - 1015 K Ohm6'b101011 - 1039 K Ohm6'b101100 - 1063 K Ohm6'b101101 - 1088 K Ohm6'b101110 - 1112 K Ohm6'b101111 - 1136 K Ohm6'b110000 - 1160 K Ohm6'b110001 - 1184 K Ohm6'b110010 - 1208 K Ohm6'b110011 - 1233 K Ohm6'b110100 - 1257 K Ohm6'b110101 - 1281 K Ohm6'b110110 - 1305 K Ohm6'b110111 - 1329 K Ohm6'b111000 - 1353 K Ohm6'b111001 - 1378 K Ohm6'b111010 - 1402 K Ohm6'b111011 - 1426 K Ohm6'b111100 - 1450 K Ohm6'b111101 - 1474 K Ohm6'b111110 - 1498 K Ohm6'b111111 - 1523 K Ohm Reset Source: mod_por_rst_n
  [7:4] LFXOSC_TRIM_I_IBIAS_COMP — Sets the COMP bias currentField values (others are reserved):4'b0000 - Base IBIAS ref x24'b0001 - Base IBIAS ref x34'b0010 - Base IBIAS ref x44'b0011 - Base IBIAS ref x54'b0100 - Base IBIAS ref x64'b0101 - Base IBIAS ref x74'b0110 - Base IBIAS ref x84'b0111 - Base IBIAS ref x94'b1000 - Base IBIAS ref x104'b1001 - Base IBIAS ref x114'b1010 - Base IBIAS ref x124'b1011 - Base IBIAS ref x134'b1100 - Base IBIAS ref x144'b1101 - Base IBIAS ref x154'b1110 - Base IBIAS ref x164'b1111 - Base IBIAS ref x17 Reset Source: mod_por_rst_n
  [3:0] LFXOSC_TRIM_R_IBIAS_REF — Sets the base IBIAS referenceField values (others are reserved):4'b0000 - 512 K Ohm4'b0001 - 576 K Ohm4'b0010 - 640 K Ohm4'b0011 - 704 K Ohm (Default)4'b0100 - 768 K Ohm4'b0101 - 832 K Ohm4'b0110 - 896 K Ohm4'b0111 - 960 K Ohm4'b1000 - 1024 K Ohm4'b1001 - 1088 K Ohm4'b1010 - 1152 K Ohm4'b1011 - 1216 K Ohm4'b1100 - 1280 K Ohm4'b1101 - 1344 K Ohm4'b1110 - 1408 K Ohm4'b1111 - 1472 K Ohm Reset Source: mod_por_rst_n
0x8050 MCU_CTRL_MMR_CFG0_MCU_PLL_CLKSEL reset 0x800000
  [31] MCU_PLL_CLKSEL_BYPASS_SW_OVRD — PLL Bypass warm reset software overrideWhen set, activates software control of exit from bypass mode on a mcu_reset_z for MCU PLL[2:0]. This bit must not be set until after the corresponding byp_warm_rst bit has been cleared or the PLL will immediately enter bypass mode. Reset Source: sys_por_rst_n
  [23] MCU_PLL_CLKSEL_BYP_WARM_RST — PLL bypass mode after warm reset.This bit is only valid when bypass_sw_ovrd is set to 1'b1 to activate bypass software override.This bit is set (1'b1) when an MCU warm reset occurs and will keep MCU PLL[2:0] in bypass mode after reset exit until cleared by software. 1'b0 = Exit bypass mode (based on MCU PLL[2:0]_CTRL_bypass_en bit value) 1'b1 = Maintain bypass mode. Reset Source: mcu_chip1_rst_n
  [8] MCU_PLL_CLKSEL_CLKLOSS_SWTCH_EN — When set, activates automatic switching of MCU PLL[2:0] clock source to CLK_12M_RC if HFOSC0 clock loss is detected Reset Source: mod_por_rst_n
0x8058 MCU_CTRL_MMR_CFG0_DEVICE_CLKOUT_32K_CTRL
  [1:0] DEVICE_CLKOUT_32K_CTRL_CLK_32K_RC_SEL — Selects the source of the device level 32KHz ClockField values (others are reserved):2'b00 - CLK_32K_RC2'b01 - HFOSC0_CLKOUT_32K2'b10 - Reserved - (implementation: CLK_32K_RC)2'b11 - LFOSC0_CLKOUT Reset Source: mod_g_rst_n
{0x8060+4i} MCU_CTRL_MMR_CFG0_MCU_TIMER{i}_CLKSEL (i=0..3)
  [2:0] MCU_TIMER{i}_CLKSEL_CLK_SEL — Timer functional clock input select mux control (Reserved values default to HFOSC0_CLK)Field values (others are reserved):3'b000 - HFOSC0_CLKOUT3'b001 - MCU_SYSCLK0 / 23'b010 - CLK_12M_RC3'b011 - MCU_PLL0_HSDIV5_CLKOUT3'b100 - MCU_EXT_REFCLK03'b101 - DEVICE_CLKOUT_32K3'b110 - CPSW_GENF03'b111 - CLK_32K_RC Reset Source: sys_por_rst_n
